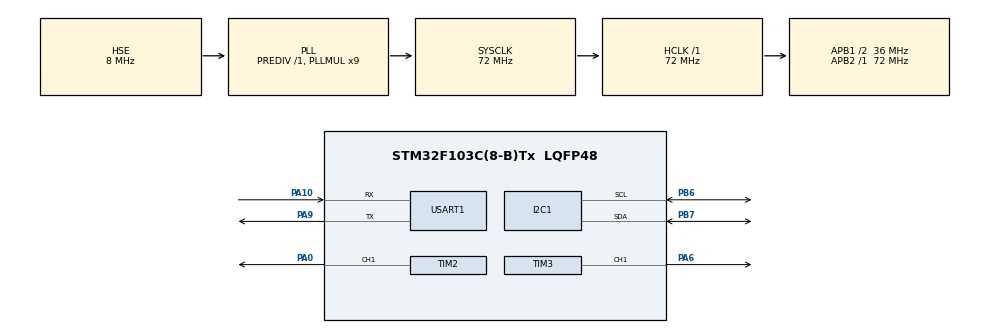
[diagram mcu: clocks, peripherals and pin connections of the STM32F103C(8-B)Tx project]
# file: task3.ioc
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I2C1.I2C_Mode=I2C_Standard
Mcu.Family=STM32F1
Mcu.Name=STM32F103C(8-B)Tx
Mcu.Package=LQFP48
NVIC.PriorityGroup=NVIC_PRIORITYGROUP_4
PA0-WKUP.Signal=S_TIM2_CH1_ETR
PA10.Mode=Asynchronous
PA10.Signal=USART1_RX
PA13.Mode=Serial_Wire
PA13.Signal=SYS_JTMS-SWDIO
PA14.Mode=Serial_Wire
PA14.Signal=SYS_JTCK-SWCLK
PA6.Signal=S_TIM3_CH1
PA9.Mode=Asynchronous
PA9.Signal=USART1_TX
PB6.Mode=I2C
PB6.Signal=I2C1_SCL
PB7.Mode=I2C
PB7.Signal=I2C1_SDA
PD0-OSC_IN.Mode=HSE-External-Oscillator
PD0-OSC_IN.Signal=RCC_OSC_IN
PD1-OSC_OUT.Mode=HSE-External-Oscillator
PD1-OSC_OUT.Signal=RCC_OSC_OUT
ProjectManager.HeapSize=0x200
ProjectManager.StackSize=0x400
ProjectManager.TargetToolchain=CMake
RCC.AHBFreq_Value=72000000
RCC.APB1CLKDivider=RCC_HCLK_DIV2
RCC.APB1Freq_Value=36000000
RCC.APB1TimFreq_Value=72000000
RCC.APB2Freq_Value=72000000
RCC.APB2TimFreq_Value=72000000
RCC.HCLKFreq_Value=72000000
RCC.PLLMUL=RCC_PLL_MUL9
RCC.PLLSourceVirtual=RCC_PLLSOURCE_HSE
RCC.SYSCLKFreq_VALUE=72000000
RCC.SYSCLKSource=RCC_SYSCLKSOURCE_PLLCLK
RCC.USBFreq_Value=72000000
SH.S_TIM2_CH1_ETR.0=TIM2_CH1,PWM Generation1 CH1
SH.S_TIM3_CH1.0=TIM3_CH1,PWM Generation1 CH1
TIM1.Period=45000
TIM1.Prescaler=32-1
TIM2.Channel-PWM\ Generation1\ CH1=TIM_CHANNEL_1
TIM2.Period=45000
TIM2.Prescaler=32
TIM3.Channel-PWM\ Generation1\ CH1=TIM_CHANNEL_1
TIM3.Period=45000
TIM3.Prescaler=32-1
USART1.VirtualMode=VM_ASYNC
VP_TIM1_VS_ClockSourceINT.Mode=Internal
VP_TIM2_VS_ClockSourceINT.Mode=Internal
VP_TIM3_VS_ClockSourceINT.Mode=Internal
board=custom

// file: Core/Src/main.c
/* USER CODE BEGIN Header */
/**
 ******************************************************************************
 * @file           : main.c
 * @brief          : Main program body
 ******************************************************************************
 * @attention
 *
 * Copyright (c) 2024 STMicroelectronics.
 * All rights reserved.
 *
 * This software is licensed under terms that can be found in the LICENSE file
 * in the root directory of this software component.
 * If no LICENSE file comes with this software, it is provided AS-IS.
 *
 ******************************************************************************
 */
/* USER CODE END Header */
#include "main.h"
#include "i2c.h"
#include "tim.h"
#include "usart.h"
#include "gpio.h"
#include <main.h>

/* USER CODE BEGIN PTD */
#include "mpu6050.h"
/* USER CODE END PTD */

void SystemClock_Config(void);

int main(void)
{

  /* MCU Configuration--------------------------------------------------------*/

  /* Reset of all peripherals, Initializes the Flash interface and the Systick. */
  HAL_Init();

  /* Configure the system clock */
  SystemClock_Config();

  /* Initialize all configured peripherals */
  MX_GPIO_Init();
  MX_I2C1_Init();
  MX_TIM1_Init();
  MX_TIM2_Init();
  MX_TIM3_Init();
  MX_USART1_UART_Init();
  HAL_Delay(10);
  MPU6050_Init();
  /* USER CODE BEGIN 2 */
  HAL_TIM_PWM_Start(&htim2, TIM_CHANNEL_1);
  HAL_TIM_PWM_Start(&htim3, TIM_CHANNEL_1);
  float Yaw, Pitch;
  float Pitch_a, Pitch_g;
  int ARR = 45000;
  float CRR1, CRR2;

  /* USER CODE END 2 */

  /* Infinite loop */
  while (1)
  {
    while (1)
    {
      MPU6050_Read_Accel();
      MPU6050_Read_Gyro();
      MPU6050_Read_Accel();
      MPU6050_Read_Gyro();

      // Yaw轴 直接读取陀螺仪数据
      Yaw = Yaw + (int)Gz * 0.003; // 陀螺仪的问题这里调整了角度计算
      Pitch_a = -atan2(Ay, Az) / 3.14 * 180;
      Pitch_g = Pitch + Gx * 0.005;
      // Pitch轴 互补滤波法滤波

      Pitch = 0.1 * Pitch_a + 0.9 * Pitch_g;
      CRR2 = (Pitch / 18.0 + 7.5) / 100.0;
      CRR1 = (Yaw / 18.0 + 7.5) / 100.0;

      // int err1=Yaw/90;
      // CRR1=CRR1+k*err1;貌似这个更符合动态调整一些，
      CRR1 = 0.15 - CRR1;
      CRR2 = 0.15 - CRR2; // 直接取反了这里
      int crr1 = CRR1 * ARR;
      __HAL_TIM_SET_COMPARE(&htim2, TIM_CHANNEL_1, crr1);

      // CRR2 检查和设置
      if (CRR2 < 0.025)
        CRR2 = 0.025;
      else if (CRR2 > 0.125)
        CRR2 = 0.125;

      int crr2 = CRR2 * ARR;
      __HAL_TIM_SET_COMPARE(&htim3, TIM_CHANNEL_1, crr2);
    }
  }
}

void SystemClock_Config(void)
{
  RCC_OscInitTypeDef RCC_OscInitStruct = {0};
  RCC_ClkInitTypeDef RCC_ClkInitStruct = {0};

  /** Initializes the RCC Oscillators according to the specified parameters
   * in the RCC_OscInitTypeDef structure.
   */
  RCC_OscInitStruct.OscillatorType = RCC_OSCILLATORTYPE_HSE;
  RCC_OscInitStruct.HSEState = RCC_HSE_ON;
  RCC_OscInitStruct.HSEPredivValue = RCC_HSE_PREDIV_DIV1;
  RCC_OscInitStruct.HSIState = RCC_HSI_ON;
  RCC_OscInitStruct.PLL.PLLState = RCC_PLL_ON;
  RCC_OscInitStruct.PLL.PLLSource = RCC_PLLSOURCE_HSE;
  RCC_OscInitStruct.PLL.PLLMUL = RCC_PLL_MUL9;
  if (HAL_RCC_OscConfig(&RCC_OscInitStruct) != HAL_OK)
  {
    Error_Handler();
  }

  /** Initializes the CPU, AHB and APB buses clocks
   */
  RCC_ClkInitStruct.ClockType = RCC_CLOCKTYPE_HCLK | RCC_CLOCKTYPE_SYSCLK | RCC_CLOCKTYPE_PCLK1 | RCC_CLOCKTYPE_PCLK2;
  RCC_ClkInitStruct.SYSCLKSource = RCC_SYSCLKSOURCE_PLLCLK;
  RCC_ClkInitStruct.AHBCLKDivider = RCC_SYSCLK_DIV1;
  RCC_ClkInitStruct.APB1CLKDivider = RCC_HCLK_DIV2;
  RCC_ClkInitStruct.APB2CLKDivider = RCC_HCLK_DIV1;

  if (HAL_RCC_ClockConfig(&RCC_ClkInitStruct, FLASH_LATENCY_2) != HAL_OK)
  {
    Error_Handler();
  }
}

void Error_Handler(void)
{
  __disable_irq();
  while (1)
  {
  }
}
